# PIC16F18877 register map
File version: 1.0
Registers are 8-bit, read-write, reset 0x0 unless marked. A register's access mark holds for its fields unless they carry their own. Offsets are from the block's base; [hi:lo] are bit positions; {n}, {i} and the like mark numbered series; 'fields as' and 'values as' point back to an identical list.

## OTHER — Other registers
Base 0x0080008E
0x00 ADPREVL — ADPREVL, data address 0x08e
0x01 ADPREVH — ADPREVH, data address 0x08f
0x02 ADACCL reset not defined — ADACCL, data address 0x090
0x03 ADACCH reset not defined — ADACCH, data address 0x091
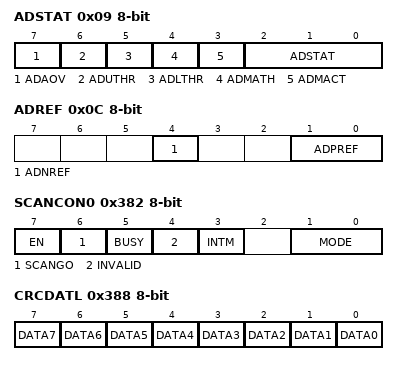
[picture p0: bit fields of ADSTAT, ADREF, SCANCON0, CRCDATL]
0x09 ADSTAT — ADSTAT, data address 0x097
  [7] ADAOV, [6] ADUTHR, [5] ADLTHR, [4] ADMATH, [3] ADMACT, [2:0] ADSTAT
0x0C ADREF — ADREF, data address 0x09a
  [4] ADNREF, [1:0] ADPREF
0x0E ADPRE — ADPRE, data address 0x09c
0x0F ADACQ — ADACQ, data address 0x09d
0x10 ADPCH — ADPCH, data address 0x09e
  [5:0] ADPCH
0x7F ADRPT — ADRPT, data address 0x10d
0x80 ADLTHL — ADLTHL, data address 0x10e
0x81 ADLTHH — ADLTHH, data address 0x10f
0x82 ADUTHL — ADUTHL, data address 0x110
0x83 ADUTHH — ADUTHH, data address 0x111
0x84 ADSTPTL — ADSTPTL, data address 0x112
0x85 ADSTPTH — ADSTPTH, data address 0x113
0x86 ADFLTRL reset not defined — ADFLTRL, data address 0x114
0x87 ADFLTRH reset not defined — ADFLTRH, data address 0x115
0x88 ADERRL — ADERRL, data address 0x116
0x89 ADERRH — ADERRH, data address 0x117
0x1FE T2TMR — T2TMR, data address 0x28c
  [7:0] TMR2
0x1FF T2PR reset 0xFF — T2PR, data address 0x28d
  [7:0] PR2
0x204 T4TMR — T4TMR, data address 0x292
  [7:0] TMR4
0x205 T4PR reset 0xFF — T4PR, data address 0x293
  [7:0] PR4
0x20A T6TMR — T6TMR, data address 0x298
  [7:0] TMR6
0x20B T6PR reset 0xFF — T6PR, data address 0x299
  [7:0] PR6
0x37E SCANLADRL — SCANLADRL, data address 0x40c
  [7:0] LADRL
0x37F SCANLADRH — SCANLADRH, data address 0x40d
  [7:0] LADRH
0x380 SCANHADRL reset 0xFF — SCANHADRL, data address 0x40e
  [7:0] HADRL
0x381 SCANHADRH reset 0xFF — SCANHADRH, data address 0x40f
  [7:0] HADRH
0x382 SCANCON0 — SCANCON0, data address 0x410
  [7] EN, [6] SCANGO, [5] BUSY, [4] INVALID, [3] INTM, [1:0] MODE
0x383 SCANTRIG — SCANTRIG, data address 0x411
  [3:0] TSEL
0x388 CRCDATL reset not defined — CRCDATL, data address 0x416
  [n] DATA{n} (n=0..7)
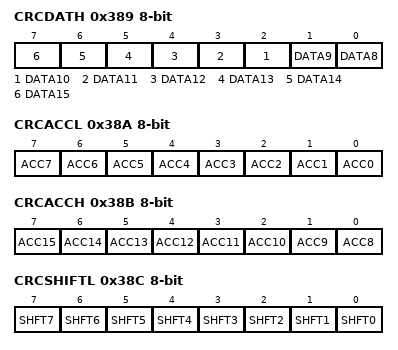
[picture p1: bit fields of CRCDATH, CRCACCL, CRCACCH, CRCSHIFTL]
0x389 CRCDATH reset not defined — CRCDATH, data address 0x417
  [n-8] DATA{n} (n=8..15)
0x38A CRCACCL — CRCACCL, data address 0x418
  [n] ACC{n} (n=0..7)
0x38B CRCACCH — CRCACCH, data address 0x419
  [n-8] ACC{n} (n=8..15)
0x38C CRCSHIFTL — CRCSHIFTL, data address 0x41a
  [n] SHFT{n} (n=0..7)
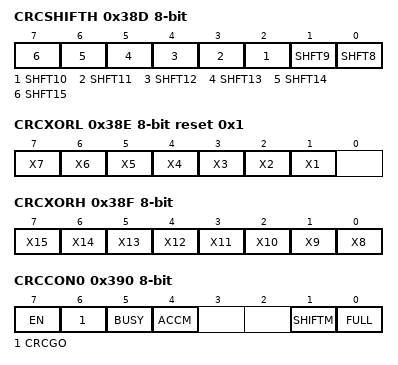
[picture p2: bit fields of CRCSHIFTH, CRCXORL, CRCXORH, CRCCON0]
0x38D CRCSHIFTH — CRCSHIFTH, data address 0x41b
  [n-8] SHFT{n} (n=8..15)
0x38E CRCXORL reset 0x1 (reset mask 0x1) — CRCXORL, data address 0x41c
  [n] X{n} (n=1..7)
0x38F CRCXORH reset not defined — CRCXORH, data address 0x41d
  [n-8] X{n} (n=8..15)
0x390 CRCCON0 — CRCCON0, data address 0x41e
  [7] EN, [6] CRCGO, [5] BUSY, [4] ACCM, [1] SHIFTM, [0] FULL
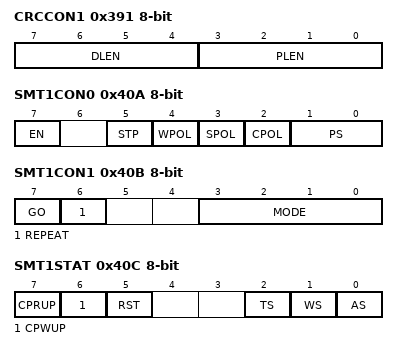
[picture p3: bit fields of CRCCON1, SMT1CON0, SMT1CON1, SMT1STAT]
0x391 CRCCON1 — CRCCON1, data address 0x41f
  [7:4] DLEN, [3:0] PLEN
0x3FE SMT1TMRL — SMT1TMRL, data address 0x48c
  [7:0] TMR
0x3FF SMT1TMRH — SMT1TMRH, data address 0x48d
  [7:0] TMR
0x400 SMT1TMRU — SMT1TMRU, data address 0x48e
  [7:0] TMR
0x401 SMT1CPRL reset not defined — SMT1CPRL, data address 0x48f
  [7:0] CPR
0x402 SMT1CPRH reset not defined — SMT1CPRH, data address 0x490
  [7:0] CPR
0x403 SMT1CPRU reset not defined — SMT1CPRU, data address 0x491
  [7:0] CPR
0x404 SMT1CPWL reset not defined — SMT1CPWL, data address 0x492
  [7:0] CPW
0x405 SMT1CPWH reset not defined — SMT1CPWH, data address 0x493
  [7:0] CPW
0x406 SMT1CPWU reset not defined — SMT1CPWU, data address 0x494
  [7:0] CPW
0x407 SMT1PRL reset 0xFF — SMT1PRL, data address 0x495
  [7:0] PR
0x408 SMT1PRH reset 0xFF — SMT1PRH, data address 0x496
  [7:0] PR
0x409 SMT1PRU reset 0xFF — SMT1PRU, data address 0x497
  [7:0] PR
0x40A SMT1CON0 — SMT1CON0, data address 0x498
  [7] EN, [5] STP, [4] WPOL, [3] SPOL, [2] CPOL, [1:0] PS
0x40B SMT1CON1 — SMT1CON1, data address 0x499
  [7] GO, [6] REPEAT, [3:0] MODE
0x40C SMT1STAT — SMT1STAT, data address 0x49a
  [7] CPRUP, [6] CPWUP, [5] RST, [2] TS, [1] WS, [0] AS
0x40D SMT1CLK — SMT1CLK, data address 0x49b
  [2:0] CSEL
0x40E SMT1SIG — SMT1SIG, data address 0x49c
  [4:0] SSEL
0x40F SMT1WIN — SMT1WIN, data address 0x49d
  [4:0] WSEL
0x47E SMT2TMRL — SMT2TMRL, data address 0x50c
  [7:0] TMR
0x47F SMT2TMRH — SMT2TMRH, data address 0x50d
  [7:0] TMR
0x480 SMT2TMRU — SMT2TMRU, data address 0x50e
  [7:0] TMR
0x481 SMT2CPRL reset not defined — SMT2CPRL, data address 0x50f
  [7:0] CPR
0x482 SMT2CPRH reset not defined — SMT2CPRH, data address 0x510
  [7:0] CPR
0x483 SMT2CPRU reset not defined — SMT2CPRU, data address 0x511
  [7:0] CPR
0x484 SMT2CPWL reset not defined — SMT2CPWL, data address 0x512
  [7:0] CPW
0x485 SMT2CPWH reset not defined — SMT2CPWH, data address 0x513
  [7:0] CPW
0x486 SMT2CPWU reset not defined — SMT2CPWU, data address 0x514
  [7:0] CPW
0x487 SMT2PRL reset 0xFF — SMT2PRL, data address 0x515
  [7:0] PR
0x488 SMT2PRH reset 0xFF — SMT2PRH, data address 0x516
  [7:0] PR
0x489 SMT2PRU reset 0xFF — SMT2PRU, data address 0x517
  [7:0] PR
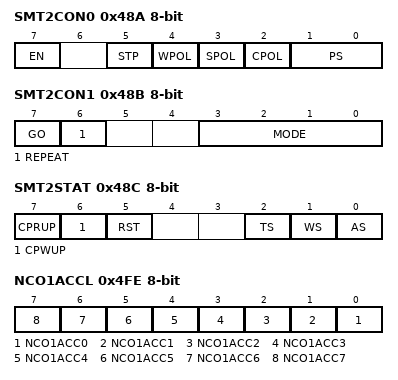
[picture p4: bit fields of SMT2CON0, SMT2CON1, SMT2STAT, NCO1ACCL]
0x48A SMT2CON0 — SMT2CON0, data address 0x518
  [7] EN, [5] STP, [4] WPOL, [3] SPOL, [2] CPOL, [1:0] PS
0x48B SMT2CON1 — SMT2CON1, data address 0x519
  [7] GO, [6] REPEAT, [3:0] MODE
0x48C SMT2STAT — SMT2STAT, data address 0x51a
  [7] CPRUP, [6] CPWUP, [5] RST, [2] TS, [1] WS, [0] AS
0x48D SMT2CLK — SMT2CLK, data address 0x51b
  [2:0] CSEL
0x48E SMT2SIG — SMT2SIG, data address 0x51c
  [4:0] SSEL
0x48F SMT2WIN — SMT2WIN, data address 0x51d
  [4:0] WSEL
0x4FE NCO1ACCL — NCO1ACCL, data address 0x58c
  [n] NCO1ACC{n} (n=0..7)
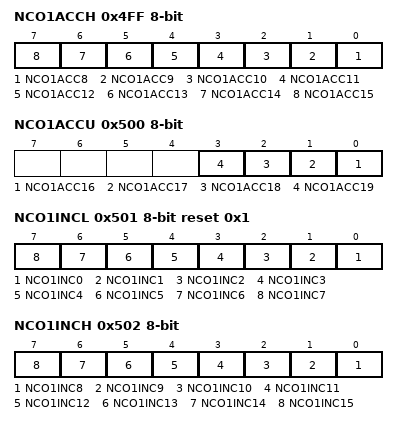
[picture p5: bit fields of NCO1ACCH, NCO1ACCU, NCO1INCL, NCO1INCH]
0x4FF NCO1ACCH — NCO1ACCH, data address 0x58d
  [n-8] NCO1ACC{n} (n=8..15)
0x500 NCO1ACCU — NCO1ACCU, data address 0x58e
  [n-16] NCO1ACC{n} (n=16..19)
0x501 NCO1INCL reset 0x1 — NCO1INCL, data address 0x58f
  [n] NCO1INC{n} (n=0..7)
0x502 NCO1INCH — NCO1INCH, data address 0x590
  [n-8] NCO1INC{n} (n=8..15)
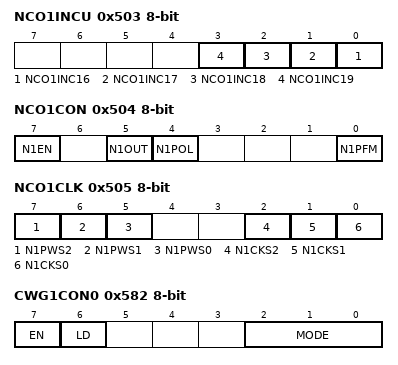
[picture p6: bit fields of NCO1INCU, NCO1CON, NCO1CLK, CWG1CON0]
0x503 NCO1INCU — NCO1INCU, data address 0x591
  [n-16] NCO1INC{n} (n=16..19)
0x504 NCO1CON — NCO1CON, data address 0x592
  [7] N1EN, [5] N1OUT, [4] N1POL, [0] N1PFM
0x505 NCO1CLK — NCO1CLK, data address 0x593
  [7] N1PWS2, [6] N1PWS1, [5] N1PWS0, [2] N1CKS2, [1] N1CKS1, [0] N1CKS0
0x57E CWG1CLKCON — CWG1CLKCON, data address 0x60c
  [0] CS
0x57F CWG1ISM — CWG1ISM, data address 0x60d
  [3:0] IS
0x580 CWG1DBR — CWG1DBR, data address 0x60e
  [5:0] DBR
0x581 CWG1DBF — CWG1DBF, data address 0x60f
  [5:0] DBF
0x582 CWG1CON0 — CWG1CON0, data address 0x610
  [7] EN, [6] LD, [2:0] MODE
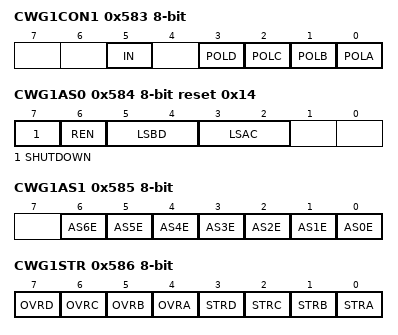
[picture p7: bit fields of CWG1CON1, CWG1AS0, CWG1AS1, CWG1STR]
0x583 CWG1CON1 (reset mask 0xF) — CWG1CON1, data address 0x611
  [5] IN, [3] POLD, [2] POLC, [1] POLB, [0] POLA
0x584 CWG1AS0 reset 0x14 — CWG1AS0, data address 0x612
  [7] SHUTDOWN, [6] REN, [5:4] LSBD, [3:2] LSAC
0x585 CWG1AS1 — CWG1AS1, data address 0x613
  [n] AS{n}E (n=0..6)
0x586 CWG1STR — CWG1STR, data address 0x614
  [7] OVRD, [6] OVRC, [5] OVRB, [4] OVRA, [3] STRD, [2] STRC, [1] STRB, [0] STRA
0x588 CWG2CLKCON — CWG2CLKCON, data address 0x616
  [0] CS
0x589 CWG2ISM — CWG2ISM, data address 0x617
  [3:0] IS
0x58A CWG2DBR — CWG2DBR, data address 0x618
  [5:0] DBR
0x58B CWG2DBF — CWG2DBF, data address 0x619
  [5:0] DBF
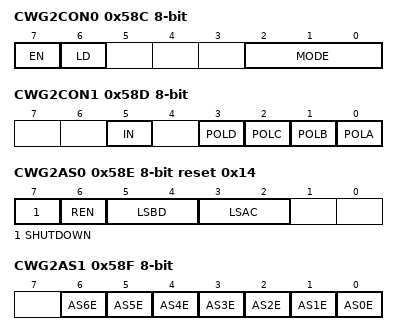
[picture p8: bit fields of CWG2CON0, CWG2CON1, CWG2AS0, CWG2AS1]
0x58C CWG2CON0 — CWG2CON0, data address 0x61a
  [7] EN, [6] LD, [2:0] MODE
0x58D CWG2CON1 (reset mask 0xF) — CWG2CON1, data address 0x61b
  [5] IN, [3] POLD, [2] POLC, [1] POLB, [0] POLA
0x58E CWG2AS0 reset 0x14 — CWG2AS0, data address 0x61c
  [7] SHUTDOWN, [6] REN, [5:4] LSBD, [3:2] LSAC
0x58F CWG2AS1 — CWG2AS1, data address 0x61d
  [n] AS{n}E (n=0..6)
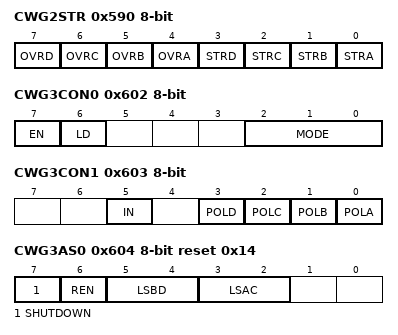
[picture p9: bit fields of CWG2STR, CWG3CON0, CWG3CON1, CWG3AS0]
0x590 CWG2STR — CWG2STR, data address 0x61e
  fields as CWG1STR
0x5FE CWG3CLKCON — CWG3CLKCON, data address 0x68c
  [0] CS
0x5FF CWG3ISM — CWG3ISM, data address 0x68d
  [3:0] IS
0x600 CWG3DBR — CWG3DBR, data address 0x68e
  [5:0] DBR
0x601 CWG3DBF — CWG3DBF, data address 0x68f
  [5:0] DBF
0x602 CWG3CON0 — CWG3CON0, data address 0x690
  [7] EN, [6] LD, [2:0] MODE
0x603 CWG3CON1 (reset mask 0xF) — CWG3CON1, data address 0x691
  [5] IN, [3] POLD, [2] POLC, [1] POLB, [0] POLA
0x604 CWG3AS0 reset 0x14 — CWG3AS0, data address 0x692
  [7] SHUTDOWN, [6] REN, [5:4] LSBD, [3:2] LSAC
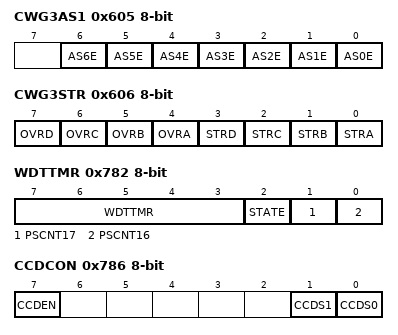
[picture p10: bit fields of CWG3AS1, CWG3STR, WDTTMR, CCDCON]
0x605 CWG3AS1 — CWG3AS1, data address 0x693
  [n] AS{n}E (n=0..6)
0x606 CWG3STR — CWG3STR, data address 0x694
  fields as CWG1STR
0x780 WDTPSL — WDTPSL, data address 0x80e
  [7:0] PSCNT
0x781 WDTPSH — WDTPSH, data address 0x80f
  [7:0] PSCNT
0x782 WDTTMR (reset mask 0x7) — WDTTMR, data address 0x810
  [7:3] WDTTMR, [2] STATE, [1] PSCNT17, [0] PSCNT16
0x786 CCDCON (reset mask 0x80) — CCDCON, data address 0x814
  [7] CCDEN, [1] CCDS1, [0] CCDS0
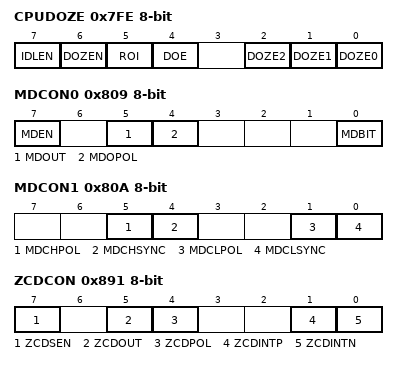
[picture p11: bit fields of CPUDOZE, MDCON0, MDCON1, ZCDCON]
0x7FE CPUDOZE — CPUDOZE, data address 0x88c
  [7] IDLEN, [6] DOZEN, [5] ROI, [4] DOE, [2] DOZE2, [1] DOZE1, [0] DOZE0
0x809 MDCON0 — MDCON0, data address 0x897
  [7] MDEN, [5] MDOUT, [4] MDOPOL, [0] MDBIT
0x80A MDCON1 — MDCON1, data address 0x898
  [5] MDCHPOL, [4] MDCHSYNC, [1] MDCLPOL, [0] MDCLSYNC
0x80B MDSRC reset not defined — MDSRC, data address 0x899
  [4:0] MDMS
0x80C MDCARL reset not defined — MDCARL, data address 0x89a
  [3:0] MDCL
0x80D MDCARH reset not defined — MDCARH, data address 0x89b
  [3:0] MDCH
0x891 ZCDCON (reset mask 0x93) — ZCDCON, data address 0x91f
  [7] ZCDSEN, [5] ZCDOUT, [4] ZCDPOL, [1] ZCDINTP, [0] ZCDINTN
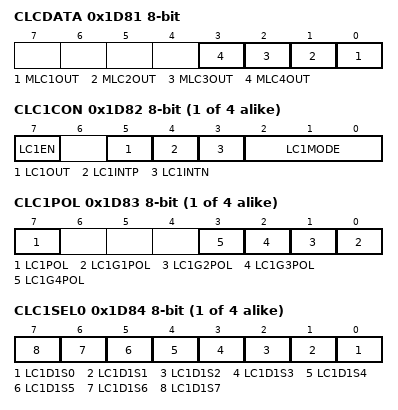
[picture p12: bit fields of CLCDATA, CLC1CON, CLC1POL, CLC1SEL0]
0x1D81 CLCDATA — CLCDATA, data address 0x1e0f
  [n-1] MLC{n}OUT (n=1..4)
{0x1D78+0xA*i} CLC{i}CON (i=1..4) — CLC{i}CON, data address {0x1E06+0xA*i}
  [7] LC{i}EN, [5] LC{i}OUT, [4] LC{i}INTP, [3] LC{i}INTN, [2:0] LC{i}MODE
{0x1D79+0xA*i} CLC{i}POL (reset mask 0x80) (i=1..4) — CLC{i}POL, data address {0x1E07+0xA*i}
  [7] LC{i}POL, [n-1] LC{i}G{n}POL (n=1..4)
{0x1D7A+0xA*i} CLC{i}SEL0 reset not defined (i=1..4) — CLC{i}SEL0, data address {0x1E08+0xA*i}
  [n] LC{i}D1S{n} (n=0..7)
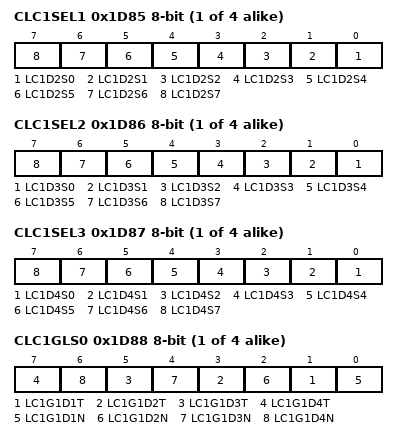
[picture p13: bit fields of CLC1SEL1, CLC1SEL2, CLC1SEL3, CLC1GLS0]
{0x1D7B+0xA*i} CLC{i}SEL1 reset not defined (i=1..4) — CLC{i}SEL1, data address {0x1E09+0xA*i}
  [n] LC{i}D2S{n} (n=0..7)
{0x1D7C+0xA*i} CLC{i}SEL2 reset not defined (i=1..4) — CLC{i}SEL2, data address {0x1E0A+0xA*i}
  [n] LC{i}D3S{n} (n=0..7)
{0x1D7D+0xA*i} CLC{i}SEL3 reset not defined (i=1..4) — CLC{i}SEL3, data address {0x1E0B+0xA*i}
  [n] LC{i}D4S{n} (n=0..7)
{0x1D7E+0xA*i} CLC{i}GLS0 reset not defined (i=1..4) — CLC{i}GLS0, data address {0x1E0C+0xA*i}
  [2n-1] LC{i}G1D{n}T (n=1..4), [2n-2] LC{i}G1D{n}N (n=1..4)
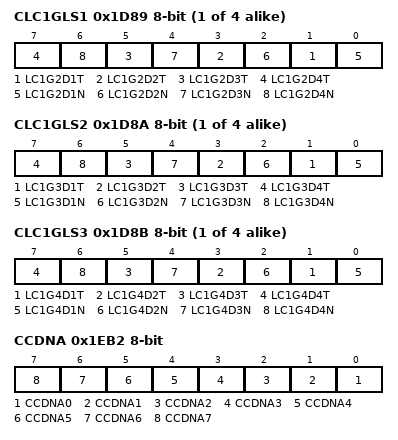
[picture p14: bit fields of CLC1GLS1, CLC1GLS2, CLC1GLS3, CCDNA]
{0x1D7F+0xA*i} CLC{i}GLS1 reset not defined (i=1..4) — CLC{i}GLS1, data address {0x1E0D+0xA*i}
  [2n-1] LC{i}G2D{n}T (n=1..4), [2n-2] LC{i}G2D{n}N (n=1..4)
{0x1D80+0xA*i} CLC{i}GLS2 reset not defined (i=1..4) — CLC{i}GLS2, data address {0x1E0E+0xA*i}
  [2n-1] LC{i}G3D{n}T (n=1..4), [2n-2] LC{i}G3D{n}N (n=1..4)
{0x1D81+0xA*i} CLC{i}GLS3 reset not defined (i=1..4) — CLC{i}GLS3, data address {0x1E0F+0xA*i}
  [2n-1] LC{i}G4D{n}T (n=1..4), [2n-2] LC{i}G4D{n}N (n=1..4)
0x1EB2 CCDNA — CCDNA, data address 0x1f40
  [n] CCDNA{n} (n=0..7)
0x1EB3 CCDPA — CCDPA, data address 0x1f41
  [n] CCDPA{n} (n=0..7)
0x1EBD CCDNB — CCDNB, data address 0x1f4b
  [n] CCDNB{n} (n=0..7)
0x1EBE CCDPB — CCDPB, data address 0x1f4c
  [n] CCDPB{n} (n=0..7)
0x1EC8 CCDNC — CCDNC, data address 0x1f56
  [n] CCDNC{n} (n=0..7)
0x1EC9 CCDPC — CCDPC, data address 0x1f57
  [n] CCDPC{n} (n=0..7)
0x1ED3 CCDND — CCDND, data address 0x1f61
  [n] CCDND{n} (n=0..7)
0x1ED4 CCDPD — CCDPD, data address 0x1f62
  [n] CCDPD{n} (n=0..7)
0x1EDE CCDNE — CCDNE, data address 0x1f6c
  [2] CCDNE2, [1] CCDNE1, [0] CCDNE0
0x1EDF CCDPE — CCDPE, data address 0x1f6d
  [2] CCDPE2, [1] CCDPE1, [0] CCDPE0
